# iostm8af61a8 register map
Registers are 8-bit, access not given, no defined reset value unless marked. A register's access mark holds for its fields unless they carry their own. Addresses are absolute; registers are grouped by the start of their names; [hi:lo] are bit positions; {n}, {i} and the like mark numbered series.

## TIM3
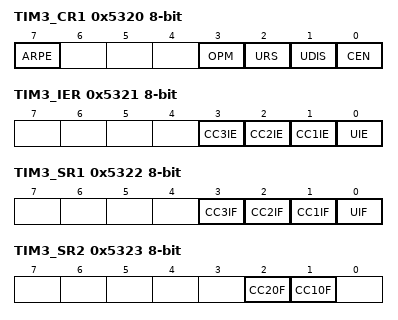
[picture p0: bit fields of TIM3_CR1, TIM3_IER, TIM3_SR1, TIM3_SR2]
0x5320 TIM3_CR1 — TIM3 control register 1
  [7] ARPE, [3] OPM, [2] URS, [1] UDIS, [0] CEN
0x5321 TIM3_IER — TIM3 interrupt enable register
  [3] CC3IE, [2] CC2IE, [1] CC1IE, [0] UIE
0x5322 TIM3_SR1 — TIM3 status register 1
  [3] CC3IF, [2] CC2IF, [1] CC1IF, [0] UIF
0x5323 TIM3_SR2 — TIM3 status register 2
  [2] CC20F, [1] CC10F
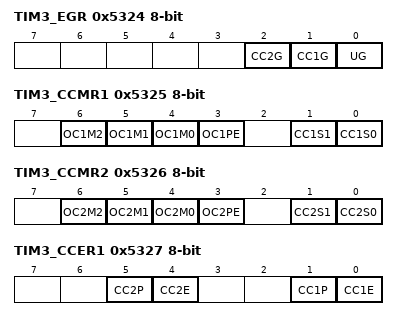
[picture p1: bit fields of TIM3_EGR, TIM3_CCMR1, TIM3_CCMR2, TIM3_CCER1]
0x5324 TIM3_EGR — TIM3 event generation register
  [2] CC2G, [1] CC1G, [0] UG
0x5325 TIM3_CCMR1 — TIM3 capture/compare mode register 1
  [6] OC1M2, [5] OC1M1, [4] OC1M0, [3] OC1PE, [1] CC1S1, [0] CC1S0
0x5326 TIM3_CCMR2 — TIM3 capture/compare mode register 2
  [6] OC2M2, [5] OC2M1, [4] OC2M0, [3] OC2PE, [1] CC2S1, [0] CC2S0
0x5327 TIM3_CCER1 — TIM3 capture/compare enable register 1
  [5] CC2P, [4] CC2E, [1] CC1P, [0] CC1E
0x5328 TIM3_CNTRH — TIM3 counter high
  [7:0] CNT
0x5329 TIM3_CNTRL — TIM3 counter low
  [7:0] CNT
0x532A TIM3_PSCR — TIM3 prescaler register
  [3:0] PSC
0x532B TIM3_ARRH — TIM3 auto-reload register high
  [7:0] ARR
0x532C TIM3_ARRL — TIM3 auto-reload register low
  [7:0] ARR
0x532D TIM3_CCR1H — TIM3 capture/compare register 1 high
  [7:0] CCR
0x532E TIM3_CCR1L — TIM3 capture/compare register 1 low
  [7:0] CCR
0x532F TIM3_CCR2H — TIM3 capture/compare register 2 high
  [7:0] CCR2
0x5330 TIM3_CCR2L — TIM3 capture/compare register 2 low
  [7:0] CCR2

## TIM4
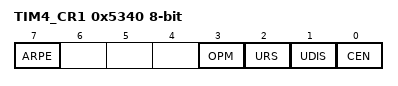
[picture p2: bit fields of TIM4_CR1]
0x5340 TIM4_CR1 — TIM4 control register 1
  [7] ARPE, [3] OPM, [2] URS, [1] UDIS, [0] CEN
0x5341 TIM4_IER — TIM4 interrupt enable register
  [0] UIE
0x5342 TIM4_SR1 — TIM4 status register
  [0] UIF
0x5343 TIM4_EGR wo — TIM4 event generation register
  [0] UG
0x5344 TIM4_CNTR — TIM4 counter
  [7:0] CNT
0x5345 TIM4_PSCR — TIM4 prescaler register
  [2:0] PSC
0x5346 TIM4_ARR — TIM4 auto-reload register

## ADC
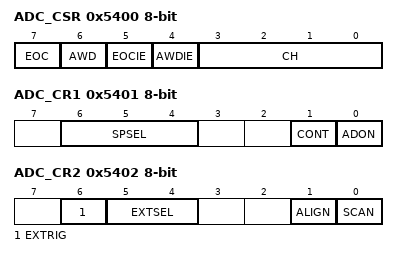
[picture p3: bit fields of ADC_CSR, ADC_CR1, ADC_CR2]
0x5400 ADC_CSR — ADC control/status register
  [7] EOC, [6] AWD, [5] EOCIE, [4] AWDIE, [3:0] CH
0x5401 ADC_CR1 — ADC configuration register 1
  [6:4] SPSEL, [1] CONT, [0] ADON
0x5402 ADC_CR2 — ADC configuration register 2
  [6] EXTRIG, [5:4] EXTSEL, [1] ALIGN, [0] SCAN
0x5404 ADC_DRH — ADC data register high
  [7:0] DATA
0x5405 ADC_DRL — ADC data register low
  [7:6] DATA
0x5406 ADC_TDRH — ADC schmitt trigger disable register high
  [7:0] TD
0x5407 ADC_TDRL — ADC schmitt trigger disable register low
  [7:0] TD

## TMU
{0x57FF+i} TMU_K{i} (i=1..8) — TMU key {i}
  [7:0] K
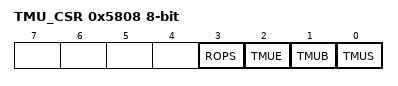
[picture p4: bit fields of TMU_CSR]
0x5808 TMU_CSR ro — TMU status register
  [3] ROPS, [2] TMUE, [1] TMUB, [0] TMUS

## CPU
0x7F00 CPU_A — Accumulator
0x7F01 CPU_PCE — Program counter extended
0x7F02 CPU_PCH — Program counter high
0x7F03 CPU_PCL — Program counter low
0x7F04 CPU_XH — X index register high
0x7F05 CPU_XL — X index register low
0x7F06 CPU_YH — Y index register high
0x7F07 CPU_YL — Y index register low
0x7F08 CPU_SPH — Stack pointer high 17h(2)
0x7F09 CPU_SPL — Stack pointer low
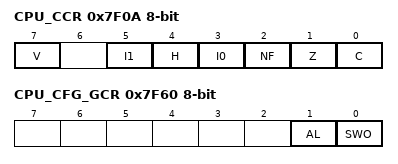
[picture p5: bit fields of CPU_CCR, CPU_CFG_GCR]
0x7F0A CPU_CCR — Condition code register
  [7] V, [5] I1, [4] H, [3] I0, [2] NF, [1] Z, [0] C
0x7F60 CPU_CFG_GCR — Global configuration register
  [1] AL, [0] SWO

## ITC
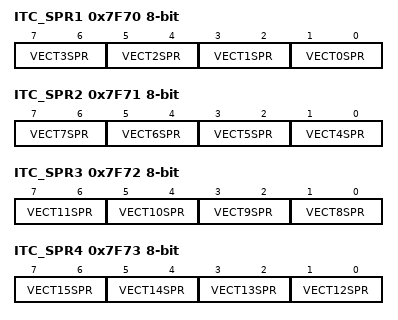
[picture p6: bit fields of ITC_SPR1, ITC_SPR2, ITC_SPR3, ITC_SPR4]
0x7F70 ITC_SPR1 — Interrupt software priority register 1
  [2n+1:2n] VECT{n}SPR (n=0..3)
0x7F71 ITC_SPR2 — Interrupt software priority register 2
  [2n-7:2n-8] VECT{n}SPR (n=4..7)
0x7F72 ITC_SPR3 — Interrupt software priority register 3
  [2n-15:2n-16] VECT{n}SPR (n=8..11)
0x7F73 ITC_SPR4 — Interrupt software priority register 4
  [2n-23:2n-24] VECT{n}SPR (n=12..15)
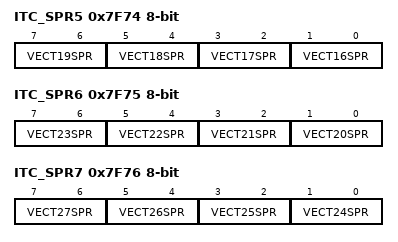
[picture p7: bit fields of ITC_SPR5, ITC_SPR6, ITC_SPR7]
0x7F74 ITC_SPR5 — Interrupt software priority register 5
  [2n-31:2n-32] VECT{n}SPR (n=16..19)
0x7F75 ITC_SPR6 — Interrupt software priority register 6
  [2n-39:2n-40] VECT{n}SPR (n=20..23)
0x7F76 ITC_SPR7 — Interrupt software priority register 7
  [2n-47:2n-48] VECT{n}SPR (n=24..27)

## DM
0x7F90 DM_BK1RE — DM breakpoint 1 register extended byte
0x7F91 DM_BK1RH — DM breakpoint 1 register high byte
0x7F92 DM_BK1RL — DM breakpoint 1 register low byte
0x7F93 DM_BK2RE — DM breakpoint 2 register extended byte
0x7F94 DM_BK2RH — DM breakpoint 2 register high byte
0x7F95 DM_BK2RL — DM breakpoint 2 register low byte
0x7F96 DM_CR1 — Debug module control register 1
0x7F97 DM_CR2 — Debug module control register 2
0x7F98 DM_CSR1 — Debug module control/status register 1
0x7F99 DM_CSR2 — Debug module control/status register 2
0x7F9A DM_ENFCTR — DM enable function register

## SFR
0x4800 OPT0 — Read-out protection (ROP)
0x4801 OPT1 — User boot code (UBC)
0x4802 NOPT1 — User boot code (UBC) (complementary byte)
0x4803 OPT2 — Alternate function remapping (AFR)
0x4804 NOPT2 — Alternate function remapping (AFR) (complementary byte)
0x4805 OPT3 — Watchdog option
0x4806 NOPT3 — Watchdog option (complementary byte)
0x4807 OPT4 — Clock option
0x4808 NOPT4 — Clock option (complementary byte)
0x4809 OPT5 — HSE clock startup
0x480A NOPT5 — HSE clock startup (complementary byte)
0x480B OPT6 — TMU
0x480C NOPT6 — TMU (complementary byte)
0x480D OPT7 — Flash wait states
0x480E NOPT7 — Flash wait states (complementary byte)
{0x4808+i} OPT{i} (i=8..15) — TMU_KEY {i-7}
0x4818 OPT16 — TMU_MAXATT
0x487E OPT17 — Bootloader
0x487F NOPT17 — Bootloader (complementary byte)
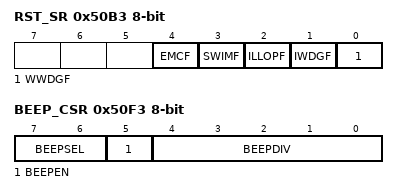
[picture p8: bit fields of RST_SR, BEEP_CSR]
0x50B3 RST_SR — Reset status register
  [4] EMCF, [3] SWIMF, [2] ILLOPF, [1] IWDGF, [0] WWDGF
0x50F3 BEEP_CSR — BEEP control/status register
  [7:6] BEEPSEL, [5] BEEPEN, [4:0] BEEPDIV
0x7F80 SWIM_CSR — SWIM control status register
